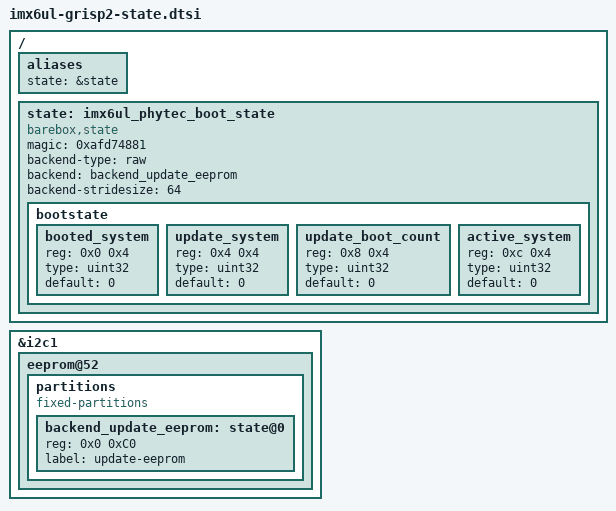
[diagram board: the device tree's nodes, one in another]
// SPDX-License-Identifier: (GPL-2.0+ OR BSD-2-Clause)
/*
 * Copyright (C) 2021 Peer Stritzinger GmbH.
 */

/ {
	aliases {
		state = &state;
	};

	state: imx6ul_phytec_boot_state {
		magic = <0xafd74881>;
		compatible = "barebox,state";
		backend-type = "raw";
		backend = <&backend_update_eeprom>;
		backend-stridesize = <64>;
		status = "okay";

		#address-cells = <1>;
		#size-cells = <1>;
		bootstate {
			#address-cells = <1>;
			#size-cells = <1>;
			booted_system {
				reg = <0x0 0x4>;
				type = "uint32";
				default = <0>;
			};
			update_system {
				reg = <0x4 0x4>;
				type = "uint32";
				default = <0>;
			};
			update_boot_count {
				reg = <0x8 0x4>;
				type = "uint32";
				default = <0>;
			};
			active_system {
				reg = <0xc 0x4>;
				type = "uint32";
				default = <0>;
			};
    		};
	};
};

&i2c1 {
	eeprom@52 {
		partitions {
			compatible = "fixed-partitions";
			#size-cells = <1>;
			#address-cells = <1>;
			backend_update_eeprom: state@0 {
				reg = <0x0 0xC0>;
				label = "update-eeprom";
			};
		};
	};
};
